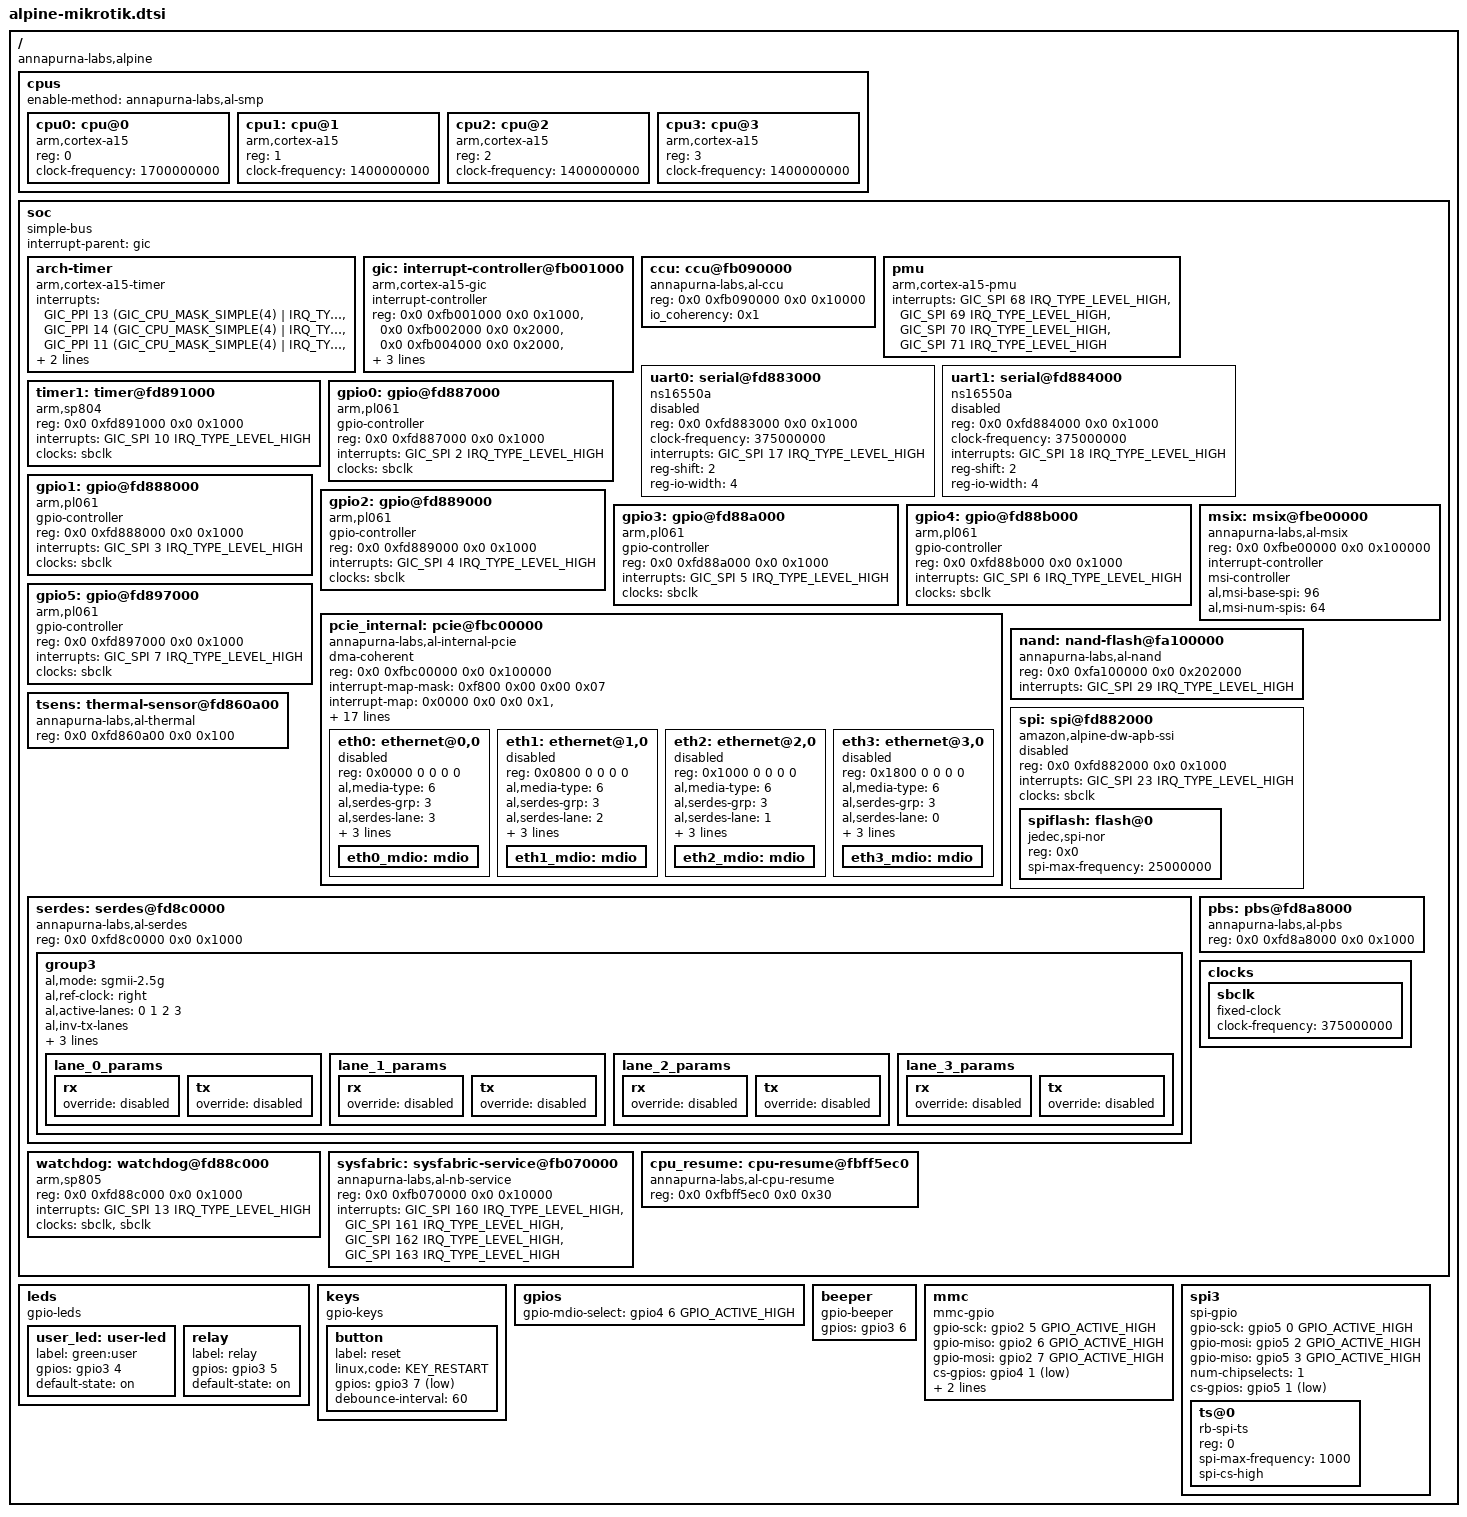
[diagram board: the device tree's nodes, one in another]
// SPDX-License-Identifier: GPL-2.0-or-later OR MIT

#include <dt-bindings/interrupt-controller/arm-gic.h>
#include <dt-bindings/interrupt-controller/irq.h>
#include <dt-bindings/gpio/gpio.h>
#include <dt-bindings/input/input.h>

/ {
	#address-cells = <2>;
	#size-cells = <2>;
	compatible = "annapurna-labs,alpine";

	cpus {
		#address-cells = <1>;
		#size-cells = <0>;
		enable-method = "annapurna-labs,al-smp";

		cpu0: cpu@0 {
			compatible = "arm,cortex-a15";
			device_type = "cpu";
			reg = <0>;
			clock-frequency = <1700000000>;
		};

		cpu1: cpu@1 {
			compatible = "arm,cortex-a15";
			device_type = "cpu";
			reg = <1>;
			clock-frequency = <1400000000>;
		};

		cpu2: cpu@2 {
			compatible = "arm,cortex-a15";
			device_type = "cpu";
			reg = <2>;
			clock-frequency = <1400000000>;
		};

		cpu3: cpu@3 {
			compatible = "arm,cortex-a15";
			device_type = "cpu";
			reg = <3>;
			clock-frequency = <1400000000>;
		};
	};

	soc: soc {
		#address-cells = <2>;
		#size-cells = <2>;
		compatible = "simple-bus";
		interrupt-parent = <&gic>;
		ranges;

		arch-timer {
			compatible = "arm,cortex-a15-timer", "arm,armv7-timer";
			interrupts =
				<GIC_PPI 13 (GIC_CPU_MASK_SIMPLE(4) | IRQ_TYPE_LEVEL_LOW)>,
				<GIC_PPI 14 (GIC_CPU_MASK_SIMPLE(4) | IRQ_TYPE_LEVEL_LOW)>,
				<GIC_PPI 11 (GIC_CPU_MASK_SIMPLE(4) | IRQ_TYPE_LEVEL_LOW)>,
				<GIC_PPI 10 (GIC_CPU_MASK_SIMPLE(4) | IRQ_TYPE_LEVEL_LOW)>;
			clock-frequency = <50000000>;
		};

		gic: interrupt-controller@fb001000 {
			compatible = "arm,cortex-a15-gic";
			#interrupt-cells = <3>;
			#size-cells = <0>;
			#address-cells = <0>;
			interrupt-controller;
			reg = <0x0 0xfb001000 0x0 0x1000>,
			      <0x0 0xfb002000 0x0 0x2000>,
			      <0x0 0xfb004000 0x0 0x2000>,
			      <0x0 0xfb006000 0x0 0x2000>;
			interrupts = <GIC_PPI 9 (GIC_CPU_MASK_SIMPLE(4) | IRQ_TYPE_LEVEL_HIGH)>;
		};

		ccu: ccu@fb090000 {
			compatible = "annapurna-labs,al-ccu";
			reg = <0x0 0xfb090000 0x0 0x10000>;
			io_coherency = <0x1>;
		};

		pmu {
			compatible = "arm,cortex-a15-pmu";
			interrupts = <GIC_SPI 68 IRQ_TYPE_LEVEL_HIGH>,
				     <GIC_SPI 69 IRQ_TYPE_LEVEL_HIGH>,
				     <GIC_SPI 70 IRQ_TYPE_LEVEL_HIGH>,
				     <GIC_SPI 71 IRQ_TYPE_LEVEL_HIGH>;
		};

		uart0: serial@fd883000 {
			compatible = "ns16550a";
			reg = <0x0 0xfd883000 0x0 0x1000>;
			clock-frequency = <375000000>;
			interrupts = <GIC_SPI 17 IRQ_TYPE_LEVEL_HIGH>;
			reg-shift = <2>;
			reg-io-width = <4>;
			status = "disabled";
		};

		uart1: serial@fd884000 {
			compatible = "ns16550a";
			reg = <0x0 0xfd884000 0x0 0x1000>;
			clock-frequency = <375000000>;
			interrupts = <GIC_SPI 18 IRQ_TYPE_LEVEL_HIGH>;
			reg-shift = <2>;
			reg-io-width = <4>;
			status = "disabled";
		};

		timer1: timer@fd891000 {
			compatible = "arm,sp804", "arm,primecell";
			reg = <0x0 0xfd891000 0x0 0x1000>;
			interrupts = <GIC_SPI 10 IRQ_TYPE_LEVEL_HIGH>;
			clocks = <&sbclk>;
			clock-names = "apb_pclk";
		};

		gpio0: gpio@fd887000 {
			#gpio-cells = <0x2>;
			compatible = "arm,pl061", "arm,primecell";
			gpio-controller;
			reg = <0x0 0xfd887000 0x0 0x1000>;
			interrupts = <GIC_SPI 2 IRQ_TYPE_LEVEL_HIGH>;
			clocks = <&sbclk>;
			clock-names = "apb_pclk";
		};

		gpio1: gpio@fd888000 {
			#gpio-cells = <0x2>;
			compatible = "arm,pl061", "arm,primecell";
			gpio-controller;
			reg = <0x0 0xfd888000 0x0 0x1000>;
			interrupts = <GIC_SPI 3 IRQ_TYPE_LEVEL_HIGH>;
			clocks = <&sbclk>;
			clock-names = "apb_pclk";
		};

		/* gpio2: mmc interface (sck, miso, mosi) */
		gpio2: gpio@fd889000 {
			#gpio-cells = <0x2>;
			compatible = "arm,pl061", "arm,primecell";
			gpio-controller;
			reg = <0x0 0xfd889000 0x0 0x1000>;
			interrupts = <GIC_SPI 4 IRQ_TYPE_LEVEL_HIGH>;
			clocks = <&sbclk>;
			clock-names = "apb_pclk";
		};

		/* gpio3: user-led[4], relay[5], beeper[6], button[7] */
		gpio3: gpio@fd88a000 {
			#gpio-cells = <0x2>;
			compatible = "arm,pl061", "arm,primecell";
			gpio-controller;
			reg = <0x0 0xfd88a000 0x0 0x1000>;
			interrupts = <GIC_SPI 5 IRQ_TYPE_LEVEL_HIGH>;
			clocks = <&sbclk>;
			clock-names = "apb_pclk";
		};

		/* gpio4: mmc-cs[1], mmc-pwr[2], mmc-cd[3], relay[5], mdio-select[6] */
		gpio4: gpio@fd88b000 {
			#gpio-cells = <0x2>;
			compatible = "arm,pl061", "arm,primecell";
			gpio-controller;
			reg = <0x0 0xfd88b000 0x0 0x1000>;
			interrupts = <GIC_SPI 6 IRQ_TYPE_LEVEL_HIGH>;
			clocks = <&sbclk>;
			clock-names = "apb_pclk";
		};

		/* gpio5: spi3-sck[0],cs[1],mosi[2],miso[3], monitor-select[7], mdio-select[6] */
		gpio5: gpio@fd897000 {
			#gpio-cells = <0x2>;
			compatible = "arm,pl061", "arm,primecell";
			gpio-controller;
			reg = <0x0 0xfd897000 0x0 0x1000>;
			interrupts = <GIC_SPI 7 IRQ_TYPE_LEVEL_HIGH>;
			clocks = <&sbclk>;
			clock-names = "apb_pclk";
		};

		pcie_internal: pcie@fbc00000 {
			compatible = "annapurna-labs,al-internal-pcie";
			device_type = "pci";
			dma-coherent;
			#size-cells = <0x2>;
			#address-cells = <0x3>;
			#interrupt-cells = <0x1>;
			reg = <0x0 0xfbc00000 0x0 0x100000>;
			interrupt-map-mask = <0xf800 0x00 0x00 0x07>;
			interrupt-map = <0x0000 0x0 0x0 0x1 &gic GIC_SPI 35 IRQ_TYPE_LEVEL_HIGH>,
					<0x0800 0x0 0x0 0x1 &gic GIC_SPI 36 IRQ_TYPE_LEVEL_HIGH>,
					<0x1000 0x0 0x0 0x1 &gic GIC_SPI 37 IRQ_TYPE_LEVEL_HIGH>,
					<0x1800 0x0 0x0 0x1 &gic GIC_SPI 38 IRQ_TYPE_LEVEL_HIGH>,
					<0x2000 0x0 0x0 0x1 &gic GIC_SPI 39 IRQ_TYPE_LEVEL_HIGH>,
					<0x2800 0x0 0x0 0x1 &gic GIC_SPI 40 IRQ_TYPE_LEVEL_HIGH>,
					<0x4000 0x0 0x0 0x1 &gic GIC_SPI 43 IRQ_TYPE_LEVEL_HIGH>,
					<0x4800 0x0 0x0 0x1 &gic GIC_SPI 44 IRQ_TYPE_LEVEL_HIGH>;
			ranges = <0x00000000 0x0 0x00000000 0x0 0xfbc00000 0x0 0x100000>,
				 <0x02000000 0x0 0xfe000000 0x0 0xfe000000 0x0 0x1000000>;
			bus-range = <0x0 0x0>;
			msi-parent = <&msix>;

			eth0: ethernet@0,0 {
				reg = <0x0000 0 0 0 0>;
				status = "disabled";
				al,media-type = <6>;
				al,serdes-grp = <3>;
				al,serdes-lane = <3>;
				al,mdio-freq = <1>;
				al,an-disable;
				al,dont-override-serdes;
				eth0_mdio: mdio {
					#address-cells = <1>;
					#size-cells = <0>;
				};
			};

			eth1: ethernet@1,0 {
				reg = <0x0800 0 0 0 0>;
				status = "disabled";
				al,media-type = <6>;
				al,serdes-grp = <3>;
				al,serdes-lane = <2>;
				al,mdio-freq = <1>;
				al,an-disable;
				al,dont-override-serdes;
				eth1_mdio: mdio {
					#address-cells = <1>;
					#size-cells = <0>;
				};
			};

			eth2: ethernet@2,0 {
				reg = <0x1000 0 0 0 0>;
				status = "disabled";
				al,media-type = <6>;
				al,serdes-grp = <3>;
				al,serdes-lane = <1>;
				al,mdio-freq = <1>;
				al,an-disable;
				al,dont-override-serdes;
				eth2_mdio: mdio {
					#address-cells = <1>;
					#size-cells = <0>;
				};
			};

			eth3: ethernet@3,0 {
				reg = <0x1800 0 0 0 0>;
				status = "disabled";
				al,media-type = <6>;
				al,serdes-grp = <3>;
				al,serdes-lane = <0>;
				al,mdio-freq = <1>;
				al,an-disable;
				al,dont-override-serdes;
				eth3_mdio: mdio {
					#address-cells = <1>;
					#size-cells = <0>;
				};
			};
		};

		msix: msix@fbe00000 {
			compatible = "annapurna-labs,al-msix";
			reg = <0x0 0xfbe00000 0x0 0x100000>;
			interrupt-controller;
			#interrupt-cells = <0>;
			msi-controller;
			al,msi-base-spi = <96>;
			al,msi-num-spis = <64>;
		};

		nand: nand-flash@fa100000 {
			compatible = "annapurna-labs,al-nand";
			reg = <0x0 0xfa100000 0x0 0x202000>;
			interrupts = <GIC_SPI 29 IRQ_TYPE_LEVEL_HIGH>;
			status = "okay";
		};

		spi: spi@fd882000 {
			compatible = "amazon,alpine-dw-apb-ssi";
			#address-cells = <0x1>;
			#size-cells = <0x0>;
			reg = <0x0 0xfd882000 0x0 0x1000>;
			interrupts = <GIC_SPI 23 IRQ_TYPE_LEVEL_HIGH>;
			clocks = <&sbclk>;
			status = "disabled";

			spiflash: flash@0 {
				#address-cells = <1>;
				#size-cells = <1>;
				compatible = "jedec,spi-nor";
				reg = <0x0>;
				spi-max-frequency = <25000000>;
			};
		};

		tsens: thermal-sensor@fd860a00 {
			compatible = "annapurna-labs,al-thermal";
			reg = <0x0 0xfd860a00 0x0 0x100>;
			#thermal-sensor-cells = <0>;
		};

		serdes: serdes@fd8c0000 {
			compatible = "annapurna-labs,al-serdes";
			reg = <0x0 0xfd8c0000 0x0 0x1000>;
			group3 {
				al,mode = "sgmii-2.5g";
				al,ref-clock = "right";
				al,active-lanes = <0 1 2 3>;
				al,inv-tx-lanes;
				al,inv-rx-lanes;
				al,ssc = "disabled";
				al,preserve-boot-config;

				lane_0_params {
					rx { override = "disabled"; };
					tx { override = "disabled"; };
				};
				lane_1_params {
					rx { override = "disabled"; };
					tx { override = "disabled"; };
				};
				lane_2_params {
					rx { override = "disabled"; };
					tx { override = "disabled"; };
				};
				lane_3_params {
					rx { override = "disabled"; };
					tx { override = "disabled"; };
				};
			};
		};

		pbs: pbs@fd8a8000 {
			compatible = "annapurna-labs,al-pbs";
			reg = <0x0 0xfd8a8000 0x0 0x1000>;
		};

		watchdog: watchdog@fd88c000 {
			compatible = "arm,sp805", "arm,primecell";
			reg = <0x0 0xfd88c000 0x0 0x1000>;
			interrupts = <GIC_SPI 13 IRQ_TYPE_LEVEL_HIGH>;
			clocks = <&sbclk>, <&sbclk>;
			clock-names = "wdog_clk", "apb_pclk";
		};

		sysfabric: sysfabric-service@fb070000 {
			compatible = "annapurna-labs,al-nb-service", "syscon";
			reg = <0x0 0xfb070000 0x0 0x10000>;
			interrupts = <GIC_SPI 160 IRQ_TYPE_LEVEL_HIGH>,
				     <GIC_SPI 161 IRQ_TYPE_LEVEL_HIGH>,
				     <GIC_SPI 162 IRQ_TYPE_LEVEL_HIGH>,
				     <GIC_SPI 163 IRQ_TYPE_LEVEL_HIGH>;
		};

		cpu_resume: cpu-resume@fbff5ec0 {
			compatible = "annapurna-labs,al-cpu-resume";
			reg = <0x0 0xfbff5ec0 0x0 0x30>;
		};

		clocks {
			#address-cells = <0x1>;
			#size-cells = <0x0>;

			sbclk: sbclk {
				#clock-cells = <0x0>;
				compatible = "fixed-clock";
				clock-frequency = <375000000>;
			};
		};
	};

	leds: leds {
		compatible = "gpio-leds";

		user_led: user-led {
			label = "green:user";
			gpios = <&gpio3 4 GPIO_ACTIVE_HIGH>;
			default-state = "on";
		};

		/* Bypass relay control - gpio3[5] */
		relay: relay {
			label = "relay";
			gpios = <&gpio3 5 GPIO_ACTIVE_HIGH>;
			default-state = "on";
		};
	};

	keys: keys {
		compatible = "gpio-keys";

		button: button {
			label = "reset";
			linux,code = <KEY_RESTART>;
			gpios = <&gpio3 7 GPIO_ACTIVE_LOW>;
			debounce-interval = <60>;
		};
	};

	gpios {
		gpio-mdio-select = <&gpio4 6 GPIO_ACTIVE_HIGH>;
	};

	beeper: beeper {
		compatible = "gpio-beeper";
		gpios = <&gpio3 6 GPIO_ACTIVE_HIGH>;
	};

	mmc: mmc {
		compatible = "mmc-gpio";
		gpio-sck  = <&gpio2 5 GPIO_ACTIVE_HIGH>;
		gpio-miso = <&gpio2 6 GPIO_ACTIVE_HIGH>;
		gpio-mosi = <&gpio2 7 GPIO_ACTIVE_HIGH>;
		cs-gpios  = <&gpio4 1 GPIO_ACTIVE_LOW>;
		gpio-power-en = <&gpio4 2 GPIO_ACTIVE_HIGH>;
		gpio-cd   = <&gpio4 3 GPIO_ACTIVE_LOW>;
	};

	spi3: spi3 {
		compatible = "spi-gpio";
		#address-cells = <0x1>;
		#size-cells = <0x0>;
		gpio-sck  = <&gpio5 0 GPIO_ACTIVE_HIGH>;
		gpio-mosi = <&gpio5 2 GPIO_ACTIVE_HIGH>;
		gpio-miso = <&gpio5 3 GPIO_ACTIVE_HIGH>;
		num-chipselects = <1>;
		cs-gpios  = <&gpio5 1 GPIO_ACTIVE_LOW>;

		ts@0 {
			compatible = "rb-spi-ts";
			reg = <0>;
			spi-max-frequency = <1000>;
			spi-cs-high;
		};
	};
};
